# ATtiny12 device description
Architecture: AVR8; Family: tinyAVR
Programming and debug interfaces: ISP, HVSP
Registers are 8-bit, access not given, no defined reset value unless marked. A register's access mark holds for its fields unless they carry their own. Offsets are from the block's base; lines under a group give offsets from that group; [hi:lo] are bit positions; {n}, {i} and the like mark numbered series; 'fields as' and 'values as' point back to an identical list; <NAME> marks a mode.

## Ordering variants
standard: 1.8 to 5.5 V

## Memory
prog space: start 0x0000 size 0x0400, little endian
  0x0000 FLASH size 0x0400 flash, rw, executable, page 0x00
signatures space: start 0 size 3, little endian
  0 SIGNATURES size 3 signatures, ro
fuses space: start 0 size 0x0001, little endian
  0 FUSES size 0x0001 fuses, rw
lockbits space: start 0 size 0x0001, little endian
  0 LOCKBITS size 0x0001 lockbits, rw
data space: start 0x0000 size 0x0060, little endian
  0x0000 REGISTERS size 0x0020 regs
  0x0020 MAPPED_IO size 0x0040 io
eeprom space: start 0x0000 size 0x0040, little endian
  0x0000 EEPROM size 0x0040 eeprom, rw, page 0x02
io space: start 0x00 size 0x40, little endian
osccal space: start 0 size 1, little endian
  0 OSCCAL size 1 osccal, ro

## Peripheral instances (address, pins/pin function, parameters)
AC at 0x00 — Analog Comparator
CPU at 0x00 — CPU Registers
EXINT at 0x00 — External Interrupts
EEPROM at 0x00
PORTB at 0x00 — I/O Port
TC0 at 0x00 — Timer/Counter, 8-bit
WDT at 0x00 — Watchdog Timer
FUSE at 0 in fuses — Fuses
LOCKBIT at 0 in lockbits — Lockbits

## Interrupts
0 RESET — External Reset, Power-on Reset and Watchdog Reset
1 INT0 — External Interrupt 0
2 IO_PINS — External Interrupt Request 0
3 TIMER0_OVF — Timer/Counter0 Overflow
4 EE_RDY — EEPROM Ready
5 ANA_COMP — Analog Comparator

## Properties
SIGNATURES: SIGNATURE0=0x1e, SIGNATURE1=0x90, SIGNATURE2=0x05

## FUSE — Fuses
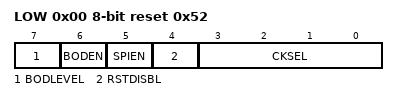
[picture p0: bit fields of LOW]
0x00 LOW reset 0x52
  [7] BODLEVEL — Brown-out Detection Level
    1=1V8 (Brown-out detection at VCC=1.8 V); 0=2V7 (Brown-out detection at VCC=2.7 V)
  [6] BODEN — Brown-out detection enabled
  [5] SPIEN — Serial program downloading (SPI) enabled
  [4] RSTDISBL — External reset function of PB5 disabled
  [3:0] CKSEL — Clock Select
    {v}=EXTXTALCRES (External Crystal / Ceramic Resonator) (v=10..15); 9=EXTLOFXTAL (External Low-Frequency Crystal); 8=EXTLOFXTAL (External Low-Frequency Crystal); 7=EXTRCOSC (External RC Ocsillator); 6=EXTRCOSC (External RC Ocsillator); 5=EXTRCOSC (External RC Ocsillator); 4=INTRCOSC (Internal RC Ocsillator); 3=INTRCOSC (Internal RC Ocsillator); 2=INTRCOSC (Internal RC Ocsillator); 1=EXTCLK (External Clock); 0=EXTCLK (External Clock)

## LOCKBIT — Lockbits
0x00 LOCKBIT
  [2:1] LB — Memory Lock
    0=PROG_VER_DISABLED (Further programming and verification disabled); 1=PROG_DISABLED (Further programming disabled); 3=NO_LOCK (No memory lock features enabled)

## AC — Analog Comparator
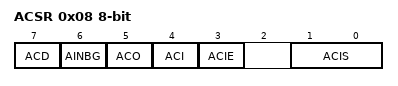
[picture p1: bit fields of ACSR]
0x08 ACSR — Analog Comparator Control And Status Register
  [7] ACD — Analog Comparator Disable
  [6] AINBG — Analog Comparator Bandgap Select
  [5] ACO — Analog Comparator Output
  [4] ACI — Analog Comparator Interrupt Flag
  [3] ACIE — Analog Comparator Interrupt Enable
  [1:0] ACIS — Analog Comparator Interrupt Mode Select bits
    0=Interrupt on Toggle; 2=Interrupt on Falling Edge; 3=Interrupt on Rising Edge

## CPU — CPU Registers
Parameters: CORE_VERSION=V0E
0x31 OSCCAL — Status Register
  [7:0] OSCCAL — Oscillator Calibration
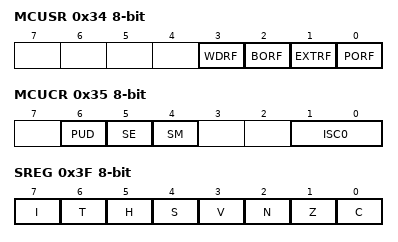
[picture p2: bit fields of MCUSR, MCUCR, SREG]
0x34 MCUSR — MCU Status register
  [3] WDRF — Watchdog Reset Flag
  [2] BORF — Brown-out Reset Flag
  [1] EXTRF — External Reset Flag
  [0] PORF — Power-On Reset Flag
0x35 MCUCR — MCU Control Register
  [6] PUD — Pull-up Disable
  [5] SE — Sleep Enable
  [4] SM — Sleep Mode
    0=IDLE; 1=PDOWN (Power Down)
  [1:0] ISC0 — Interrupt Sense Control 0 bits
    0=Low Level of INTX; 1=Any Logical Change in INTX; 2=Falling Edge of INTX; 3=Rising Edge of INTX
0x3F SREG — Status Register
  [7] I — Global Interrupt Enable
  [6] T — Bit Copy Storage
  [5] H — Half Carry Flag
  [4] S — Sign Bit
  [3] V — Two's Complement Overflow Flag
  [2] N — Negative Flag
  [1] Z — Zero Flag
  [0] C — Carry Flag
Value list OSCCAL_VALUE_ADDRESSES: 0=1_2_MHz

## EXINT — External Interrupts
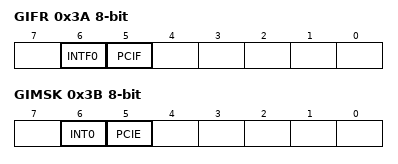
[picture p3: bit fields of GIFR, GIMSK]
0x3A GIFR — General Interrupt Flag register
  [6] INTF0 — External Interrupt Flag 0
  [5] PCIF — Pin Change Interrupt Flag
0x3B GIMSK — General Interrupt Mask Register
  [6] INT0 — External Interrupt Request 0 Enable
  [5] PCIE — Pin Change Interrupt Enable

## EEPROM
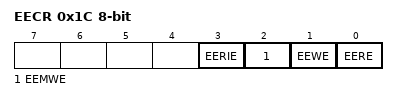
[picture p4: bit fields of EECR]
0x1C EECR — EEPROM Control Register
  [3] EERIE — EEProm Ready Interrupt Enable
  [2] EEMWE — EEPROM Master Write Enable
  [1] EEWE — EEPROM Write Enable
  [0] EERE — EEPROM Read Enable
0x1D EEDR — EEPROM Data Register
0x1E EEAR bits used 5:0 — EEPROM Read/Write Access

## PORTB — I/O Port
0x16 PINB bits used 5:0 — Input Pins, Port B
0x17 DDRB bits used 5:0 — Data Direction Register, Port B
0x18 PORTB bits used 4:0 — Data Register, Port B

## TC0 (TC8 module) — Timer/Counter, 8-bit
0x32 TCNT0 — Timer Counter 0
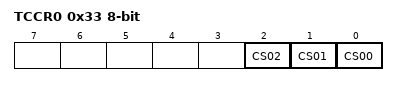
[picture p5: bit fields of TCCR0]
0x33 TCCR0 — Timer/Counter0 Control Register
  [2] CS02 — Clock Select0 bit 2
    0=No Clock Source (Stopped); 1=Running, No Prescaling; 2=Running, CLK/8; 3=Running, CLK/64; 4=Running, CLK/256; 5=Running, CLK/1024; 6=Running, ExtClk Tx Falling Edge; 7=Running, ExtClk Tx Rising Edge
  [1] CS01 — Clock Select0 bit 1
  [0] CS00 — Clock Select0 bit 0
0x38 TIFR — Timer/Counter Interrupt Flag register
  [1] TOV0 — Timer/Counter0 Overflow Flag
0x39 TIMSK — Timer/Counter Interrupt Mask Register
  [1] TOIE0 — Timer/Counter0 Overflow Interrupt Enable

## WDT — Watchdog Timer
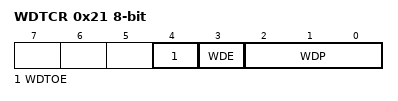
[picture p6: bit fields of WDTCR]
0x21 WDTCR — Watchdog Timer Control Register
  [4] WDTOE — RW
  [3] WDE — Watch Dog Enable
  [2:0] WDP — Watch Dog Timer Prescaler bits
    0=Oscillator Cycles 16K; 1=Oscillator Cycles 32K; 2=Oscillator Cycles 64K; 3=Oscillator Cycles 128K; 4=Oscillator Cycles 256K; 5=Oscillator Cycles 512K; 6=Oscillator Cycles 1024K; 7=Oscillator Cycles 2048K
